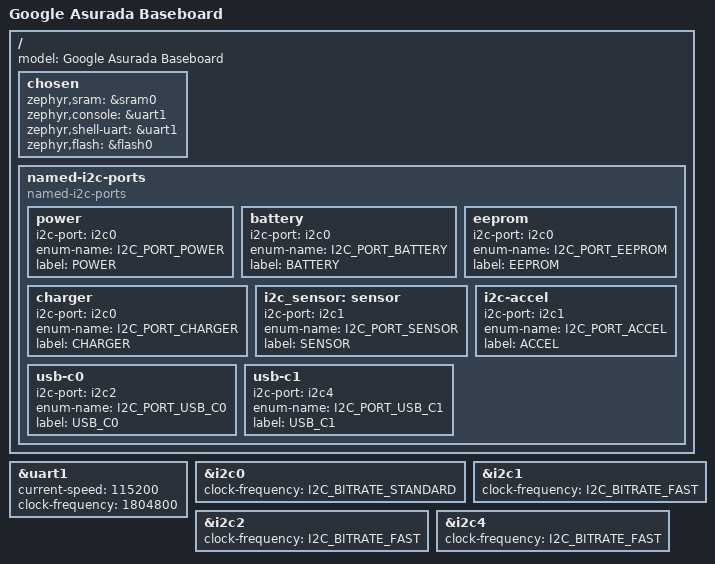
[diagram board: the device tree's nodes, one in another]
/* Copyright 2021 The Chromium OS Authors. All rights reserved.
 * Use of this source code is governed by a BSD-style license that can be
 * found in the LICENSE file.
 */

/dts-v1/;

#include <cros/ite/it8xxx2.dtsi>
#include <dt-bindings/gpio_defines.h>
#include <it8xxx2.dtsi>

/ {
	model = "Google Asurada Baseboard";

	chosen {
		zephyr,sram = &sram0;
		zephyr,console = &uart1;
		zephyr,shell-uart = &uart1;
		zephyr,flash = &flash0;
	};

	named-i2c-ports {
		compatible = "named-i2c-ports";

		power {
			i2c-port = <&i2c0>;
			enum-name = "I2C_PORT_POWER";
			label = "POWER";
		};
		battery {
			i2c-port = <&i2c0>;
			enum-name = "I2C_PORT_BATTERY";
			label = "BATTERY";
		};
		eeprom {
			i2c-port = <&i2c0>;
			enum-name = "I2C_PORT_EEPROM";
			label = "EEPROM";
		};
		charger {
			i2c-port = <&i2c0>;
			enum-name = "I2C_PORT_CHARGER";
			label = "CHARGER";
		};
		i2c_sensor: sensor {
			i2c-port = <&i2c1>;
			enum-name = "I2C_PORT_SENSOR";
			label = "SENSOR";
		};
		i2c-accel {
			i2c-port = <&i2c1>;
			enum-name = "I2C_PORT_ACCEL";
			label = "ACCEL";
		};
		usb-c0 {
			i2c-port = <&i2c2>;
			enum-name = "I2C_PORT_USB_C0";
			label = "USB_C0";
		};
		usb-c1 {
			i2c-port = <&i2c4>;
			enum-name = "I2C_PORT_USB_C1";
			label = "USB_C1";
		};
	};
};

&uart1 {
	status = "okay";
	current-speed = <115200>;
	clock-frequency = <1804800>;
};

&i2c0 {
	/* EC_I2C_PWR_CBI */
	status = "okay";
	clock-frequency = <I2C_BITRATE_STANDARD>;
};

&i2c1 {
	/* EC_I2C_SENSOR */
	status = "okay";
	clock-frequency = <I2C_BITRATE_FAST>;
};

&i2c2 {
	/* EC_I2C_USB_C0 */
	status = "okay";
	clock-frequency = <I2C_BITRATE_FAST>;
};

&i2c4{
	/* EC_I2C_USB_C1 */
	status = "okay";
	clock-frequency = <I2C_BITRATE_FAST>;
};
